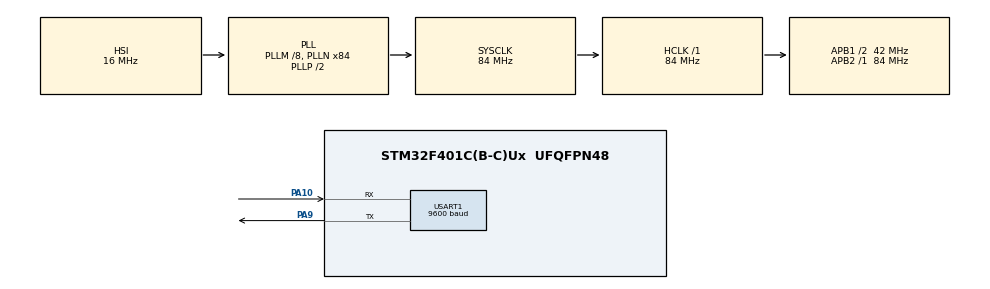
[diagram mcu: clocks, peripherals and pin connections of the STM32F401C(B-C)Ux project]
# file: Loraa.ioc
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Mcu.Family=STM32F4
Mcu.Name=STM32F401C(B-C)Ux
Mcu.Package=UFQFPN48
NVIC.PriorityGroup=NVIC_PRIORITYGROUP_4
PA10.Mode=Asynchronous
PA10.Signal=USART1_RX
PA13.Mode=Serial_Wire
PA13.Signal=SYS_JTMS-SWDIO
PA14.Mode=Serial_Wire
PA14.Signal=SYS_JTCK-SWCLK
PA9.Mode=Asynchronous
PA9.Signal=USART1_TX
PH0\ -\ OSC_IN.Mode=HSE-External-Oscillator
PH0\ -\ OSC_IN.Signal=RCC_OSC_IN
PH1\ -\ OSC_OUT.Mode=HSE-External-Oscillator
PH1\ -\ OSC_OUT.Signal=RCC_OSC_OUT
ProjectManager.HeapSize=0x200
ProjectManager.StackSize=0x400
ProjectManager.TargetToolchain=STM32CubeIDE
RCC.48MHZClocksFreq_Value=42000000
RCC.AHBFreq_Value=84000000
RCC.APB1CLKDivider=RCC_HCLK_DIV2
RCC.APB1Freq_Value=42000000
RCC.APB1TimFreq_Value=84000000
RCC.APB2Freq_Value=84000000
RCC.APB2TimFreq_Value=84000000
RCC.CortexFreq_Value=84000000
RCC.HCLKFreq_Value=84000000
RCC.HSE_VALUE=25000000
RCC.HSI_VALUE=16000000
RCC.LSE_VALUE=32768
RCC.PLLM=8
RCC.PLLN=84
RCC.SYSCLKFreq_VALUE=84000000
RCC.SYSCLKSource=RCC_SYSCLKSOURCE_PLLCLK
RCC.VCOOutputFreq_Value=168000000
USART1.BaudRate=9600
USART1.VirtualMode=VM_ASYNC
USART1.WordLength=WORDLENGTH_8B
board=custom

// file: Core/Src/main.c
/* USER CODE BEGIN Header */
/**
  ******************************************************************************
  * @file           : main.c
  * @brief          : Main program body
  ******************************************************************************
  * @attention
  *
  * Copyright (c) 2023 STMicroelectronics.
  * All rights reserved.
  *
  * This software is licensed under terms that can be found in the LICENSE file
  * in the root directory of this software component.
  * If no LICENSE file comes with this software, it is provided AS-IS.
  *
  ******************************************************************************
  */
/* USER CODE END Header */
#include "main.h"

UART_HandleTypeDef huart1;

void SystemClock_Config(void);
static void MX_GPIO_Init(void);
static void MX_USART1_UART_Init(void);

/* USER CODE BEGIN 0 */
uint8_t ADDRESSHL = 0;
uint8_t CHANNEL = 23;
uint8_t DATA[17];
char ZIRVE[4];
char DURUM; // A = YUKSELIS , B = KURTARMA1 ATES , C = KURTARMA2 ATES
uint8_t EGIMX[2],EGIMZ[2];
uint8_t HIZ[3];
uint8_t YUKSEKLIK[4];
uint8_t SICAKLIKVENEM[5];
int kalman_velocity = 5;
int kalman_gzz=28,kalman_gxx=7;
int h=186;
void sendData()
{
	if(h < 1000)
	{
		for(int i=0;i<4;i++)
		{
			DATA[i]='0';
		}
	}else
	{
		sprintf(ZIRVE, "%d",h); // 1354 metre tot "1354"
		for(int i=0;i<4;i++)
		{
			DATA[i] = ZIRVE[i];
		}
	}

	DURUM='A';
	DATA[4] = DURUM;
	sprintf(EGIMX, "%d", (int)kalman_gxx); // X VE Z EKSENİNE GÖRE E�?İM DE�?ERLERİNE STRİNGE CEVİR
	sprintf(EGIMZ, "%d", (int)kalman_gzz);
	if(kalman_gxx <10)
	{
		EGIMX[1] = EGIMX[0];
		EGIMX[0]='0';
	}
	for(int i=5;i<7;i++)
	{
		DATA[i] = EGIMX[i-5];
	}
	if(kalman_gzz <10)
	{
			EGIMZ[1] = EGIMZ[0];
			EGIMZ[0]='0';
	}
	for(int i=7;i<9;i++)
	{
		DATA[i] = EGIMZ[i-7];
	}
	sprintf(HIZ,"%d",kalman_velocity);
	if(kalman_velocity<10)
	{
		HIZ[2]=HIZ[0];
		HIZ[1]='0';
		HIZ[0] = '0';
	}else if(kalman_velocity >= 10 && kalman_velocity <100)
	{
		HIZ[2]=HIZ[1];
		HIZ[1]=HIZ[0];
		HIZ[0] = '0';
	}
	for(int i=9;i<12;i++)
	{
		DATA[i] = HIZ[i-9];
	}
	sprintf(YUKSEKLIK,"%d",h);
	if(h<10)
	{
		YUKSEKLIK[3]=YUKSEKLIK[0];
		YUKSEKLIK[2]='0';
		YUKSEKLIK[1] = '0';
		YUKSEKLIK[0]='0';
	}else if(h >= 10 && h <100)
	{
		YUKSEKLIK[3]=YUKSEKLIK[1];
		YUKSEKLIK[2]=YUKSEKLIK[0];
		YUKSEKLIK[1] = '0';
		YUKSEKLIK[0]='0';
	}else if(h >= 100 && h <1000)
	{
		YUKSEKLIK[3]=YUKSEKLIK[2];
		YUKSEKLIK[2]=YUKSEKLIK[1];
		YUKSEKLIK[1] =YUKSEKLIK[0];
		YUKSEKLIK[0]='0';
	}
	for(int i=12;i<16;i++)
	{
		DATA[i] = YUKSEKLIK[i-12];
	}
	DATA[16]='\n';
    HAL_UART_Transmit(&huart1, &ADDRESSHL, 1,20);
	HAL_UART_Transmit(&huart1, &ADDRESSHL, 1,20);
	HAL_UART_Transmit(&huart1, &CHANNEL, 1,20);
    HAL_Delay(1);
	HAL_UART_Transmit(&huart1, DATA, sizeof(DATA),200);
}
/* USER CODE END 0 */

int main(void)
{

  /* MCU Configuration--------------------------------------------------------*/

  /* Reset of all peripherals, Initializes the Flash interface and the Systick. */
  HAL_Init();

  /* Configure the system clock */
  SystemClock_Config();

  /* Initialize all configured peripherals */
  MX_GPIO_Init();
  MX_USART1_UART_Init();

  /* Infinite loop */
  while (1)
  {

    /* USER CODE BEGIN 3 */
	  sendData();
	  HAL_Delay(300);
  }
  /* USER CODE END 3 */
}

void SystemClock_Config(void)
{
  RCC_OscInitTypeDef RCC_OscInitStruct = {0};
  RCC_ClkInitTypeDef RCC_ClkInitStruct = {0};

  /** Configure the main internal regulator output voltage
  */
  __HAL_RCC_PWR_CLK_ENABLE();
  __HAL_PWR_VOLTAGESCALING_CONFIG(PWR_REGULATOR_VOLTAGE_SCALE2);

  /** Initializes the RCC Oscillators according to the specified parameters
  * in the RCC_OscInitTypeDef structure.
  */
  RCC_OscInitStruct.OscillatorType = RCC_OSCILLATORTYPE_HSI;
  RCC_OscInitStruct.HSIState = RCC_HSI_ON;
  RCC_OscInitStruct.HSICalibrationValue = RCC_HSICALIBRATION_DEFAULT;
  RCC_OscInitStruct.PLL.PLLState = RCC_PLL_ON;
  RCC_OscInitStruct.PLL.PLLSource = RCC_PLLSOURCE_HSI;
  RCC_OscInitStruct.PLL.PLLM = 8;
  RCC_OscInitStruct.PLL.PLLN = 84;
  RCC_OscInitStruct.PLL.PLLP = RCC_PLLP_DIV2;
  RCC_OscInitStruct.PLL.PLLQ = 4;
  if (HAL_RCC_OscConfig(&RCC_OscInitStruct) != HAL_OK)
  {
    Error_Handler();
  }

  /** Initializes the CPU, AHB and APB buses clocks
  */
  RCC_ClkInitStruct.ClockType = RCC_CLOCKTYPE_HCLK|RCC_CLOCKTYPE_SYSCLK
                              |RCC_CLOCKTYPE_PCLK1|RCC_CLOCKTYPE_PCLK2;
  RCC_ClkInitStruct.SYSCLKSource = RCC_SYSCLKSOURCE_PLLCLK;
  RCC_ClkInitStruct.AHBCLKDivider = RCC_SYSCLK_DIV1;
  RCC_ClkInitStruct.APB1CLKDivider = RCC_HCLK_DIV2;
  RCC_ClkInitStruct.APB2CLKDivider = RCC_HCLK_DIV1;

  if (HAL_RCC_ClockConfig(&RCC_ClkInitStruct, FLASH_LATENCY_2) != HAL_OK)
  {
    Error_Handler();
  }
}

static void MX_USART1_UART_Init(void)
{

  huart1.Instance = USART1;
  huart1.Init.BaudRate = 9600;
  huart1.Init.WordLength = UART_WORDLENGTH_8B;
  huart1.Init.StopBits = UART_STOPBITS_1;
  huart1.Init.Parity = UART_PARITY_NONE;
  huart1.Init.Mode = UART_MODE_TX_RX;
  huart1.Init.HwFlowCtl = UART_HWCONTROL_NONE;
  huart1.Init.OverSampling = UART_OVERSAMPLING_16;
  if (HAL_UART_Init(&huart1) != HAL_OK)
  {
    Error_Handler();
  }

}

static void MX_GPIO_Init(void)
{

  /* GPIO Ports Clock Enable */
  __HAL_RCC_GPIOH_CLK_ENABLE();
  __HAL_RCC_GPIOA_CLK_ENABLE();

}

void Error_Handler(void)
{
  __disable_irq();
  while (1)
  {
  }
}
